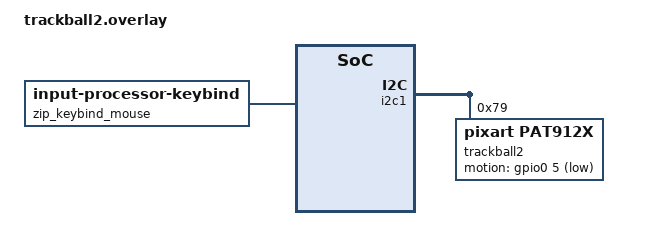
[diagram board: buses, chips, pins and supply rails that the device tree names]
#include <zephyr/dt-bindings/input/input-event-codes.h>
#include <input/processors.dtsi>
#include <input/processors/report_rate_limit.dtsi>
#include <input/processors/xyz.dtsi>
#include <input/processors/zmk-input-processor-keybind.dtsi>
#include "../pinctrl_i2c.dtsi"
#include "../listners.dtsi"


// &gpio1 {
//     sensor_wakeup {
//         gpio-hog;
//         gpios = <12 GPIO_ACTIVE_LOW>;
//         output-low;
//     };
// };

&i2c1 {
	status = "okay";
	compatible = "nordic,nrf-twim";
	pinctrl-0 = <&i2c1_default>;
	pinctrl-1 = <&i2c1_sleep>;
	pinctrl-names = "default", "sleep";
	// clock-frequency = <I2C_BITRATE_FAST>;
    // #address-cells = <1>;
    // #size-cells = <0>;

	trackball2: trackball2@79 {
		status = "okay";
		compatible = "pixart,pat912x";
		reg = <0x79>; // HIGH:0x73, LOW:0x75, NC:0x79
		motion-gpios = <&gpio0 5 (GPIO_ACTIVE_LOW | GPIO_PULL_UP)>;
		res-x-cpi = <100>;
		res-y-cpi = <100>;
		zephyr,axis-x = <INPUT_REL_X>;
		zephyr,axis-y = <INPUT_REL_Y>;
		invert-x;
		invert-y;
		sleep1-enable;
		sleep2-enable;
	};
};

&split_peripheral {
    device = <&trackball2>;
    input-processors = <&zip_report_rate_limit 8>, <&zip_xyz>, <&zip_keybind_mouse>;
    // input-processors 
	// 	= <&zip_xy_transform INPUT_TRANSFORM_X_INVERT>
	// 	, <&zip_xy_transform INPUT_TRANSFORM_Y_INVERT>
	// 	, <&zip_xy_to_scroll_mapper>
	// 	;
    // scroller {
    //     layers = <0>;
    //     input-processors = <&zip_xy_transform INPUT_TRANSFORM_X_INVERT>
    //     , <&zip_xy_transform INPUT_TRANSFORM_Y_INVERT>
    //     , <&zip_xy_to_scroll_mapper>
    //     ;
    // };
};

/ {
    zip_keybind_mouse: zip_keybind_mouse {
        compatible = "zmk,input-processor-keybind";
        #input-processor-cells = <0>;
        bindings = <&mo MOUSE>, <&mo MOUSE>, <&mo MOUSE>, <&mo MOUSE>;
        mode = <0>;
        tap-ms = <180>;
        wait-ms = <0>;
        tick = <8>;
        threshold = <1>;
        max_threshold = <200>;
        track_remainders = <false>;
    };
};

// &pointer {
//     status = "okay";
//     device = <&trackball>;
// };

// &cpi_cyc{
//     status = "okay";
//     sensor_device = <&trackball>;
// };
